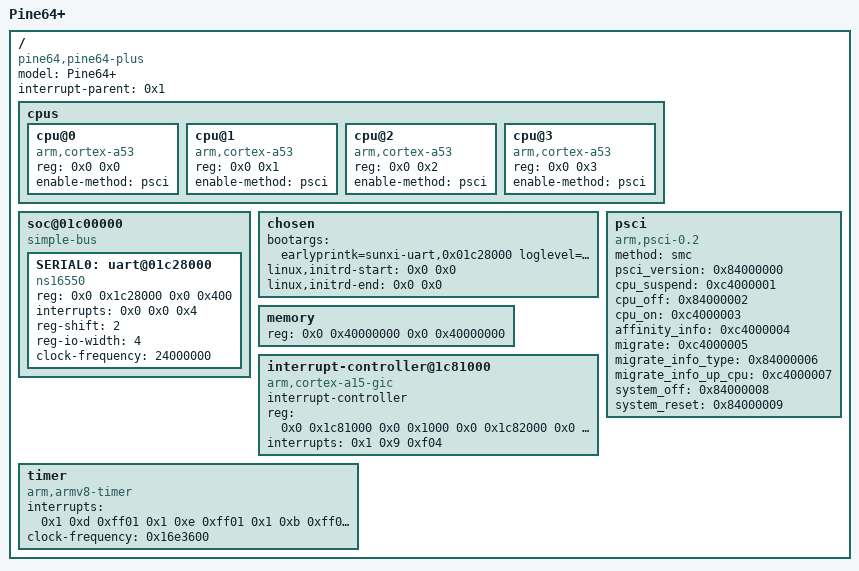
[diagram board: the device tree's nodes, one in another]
/dts-v1/;

/memreserve/	0x0000000045000000 0x0000000000200000;
/memreserve/	0x0000000041010000 0x0000000000010000;
/memreserve/	0x0000000041020000 0x0000000000000800;
/memreserve/	0x0000000040100000 0x0000000000004000;
/memreserve/	0x0000000040104000 0x0000000000001000;
/memreserve/	0x0000000040105000 0x0000000000001000;
/ {
	model = "Pine64+";
	compatible = "pine64,pine64-plus";
	interrupt-parent = <0x1>;
	#address-cells = <0x2>;
	#size-cells = <0x2>;

	cpus {
		#address-cells = <0x2>;
		#size-cells = <0x0>;

		cpu@0 {
			device_type = "cpu";
			compatible = "arm,cortex-a53", "arm,armv8";
			reg = <0x0 0x0>;
			enable-method = "psci";
		};

		cpu@1 {
			device_type = "cpu";
			compatible = "arm,cortex-a53", "arm,armv8";
			reg = <0x0 0x1>;
			enable-method = "psci";
		};

                cpu@2 {
                        device_type = "cpu";
                        compatible = "arm,cortex-a53", "arm,armv8";
                        reg = <0x0 0x2>;
                        enable-method = "psci";
                };

                cpu@3 {
                        device_type = "cpu";
                        compatible = "arm,cortex-a53", "arm,armv8";
                        reg = <0x0 0x3>;
                        enable-method = "psci";
                };
	};

	soc@01c00000 {
		compatible = "simple-bus";
		#address-cells = <0x2>;
		#size-cells = <0x2>;
		ranges;
		device_type = "soc";

		 SERIAL0: uart@01c28000 {
                        device_type = "uart0";
                        compatible = "ns16550";
                        reg = <0x0 0x1c28000 0x0 0x400>;
                        interrupts = <0x0 0x0 0x4>;
			reg-shift = <2>;
			reg-io-width = <4>;
                        status = "okay";
			clock-frequency = <24000000>;
                };

	};

	chosen {
		bootargs = "earlyprintk=sunxi-uart,0x01c28000 loglevel=8 initcall_debug=1 console=ttyS0 init=/init";
		linux,initrd-start = <0x0 0x0>;
		linux,initrd-end = <0x0 0x0>;
	};


	psci {
		compatible = "arm,psci-0.2";
		method = "smc";
		psci_version = <0x84000000>;
		cpu_suspend = <0xc4000001>;
		cpu_off = <0x84000002>;
		cpu_on = <0xc4000003>;
		affinity_info = <0xc4000004>;
		migrate = <0xc4000005>;
		migrate_info_type = <0x84000006>;
		migrate_info_up_cpu = <0xc4000007>;
		system_off = <0x84000008>;
		system_reset = <0x84000009>;
	};

	memory {
		device_type = "memory";
		reg = <0x0 0x40000000 0x0 0x40000000>;
	};

	interrupt-controller@1c81000 {
		compatible = "arm,cortex-a15-gic", "arm,cortex-a9-gic";
		#interrupt-cells = <0x3>;
		#address-cells = <0x0>;
		device_type = "gic";
		interrupt-controller;
		reg = <0x0 0x1c81000 0x0 0x1000 0x0 0x1c82000 0x0 0x2000 0x0 0x1c84000 0x0 0x2000 0x0 0x1c86000 0x0 0x2000>;
		interrupts = <0x1 0x9 0xf04>;
		linux,phandle = <0x1>;
		phandle = <0x1>;
	};

	timer {
		compatible = "arm,armv8-timer";
		interrupts = <0x1 0xd 0xff01 0x1 0xe 0xff01 0x1 0xb 0xff01 0x1 0xa 0xff01>;
		clock-frequency = <0x16e3600>;
	};

};
